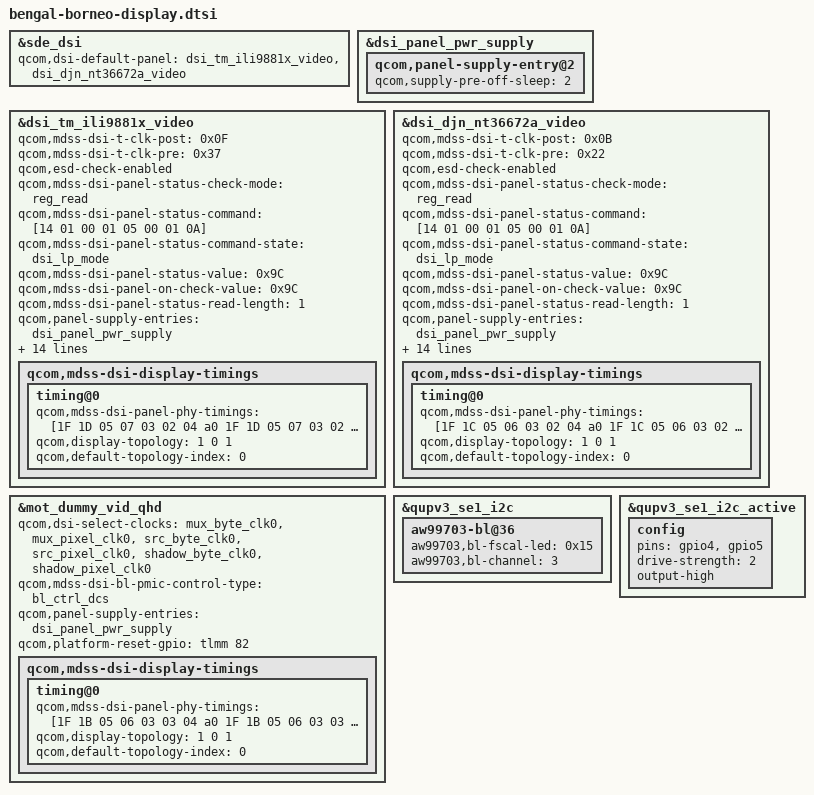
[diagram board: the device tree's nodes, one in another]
#include <dt-bindings/clock/mdss-14nm-pll-clk.h>
#include "bengal-sde-display.dtsi"
#include "bengal-leds-aw99703.dtsi"
#include "dsi-panel-mot-dummy-qhd-video.dtsi"
#include "dsi-panel-moto-ili9881x-tm-hdplus-video.dtsi"
#include "dsi-panel-moto-nt36672a-djn-hdplus-video.dtsi"

&sde_dsi {
    qcom,dsi-default-panel = <&dsi_tm_ili9881x_video &dsi_djn_nt36672a_video>;
};

&dsi_panel_pwr_supply {
	qcom,panel-supply-entry@2 {
		qcom,supply-pre-off-sleep = <2>;
	};
};

&dsi_tm_ili9881x_video {
	qcom,mdss-dsi-t-clk-post = <0x0F>;
	qcom,mdss-dsi-t-clk-pre = <0x37>;
	qcom,esd-check-enabled;
	qcom,mdss-dsi-panel-status-check-mode = "reg_read";
	qcom,mdss-dsi-panel-status-command = [14 01 00 01 05 00 01 0A];
	qcom,mdss-dsi-panel-status-command-state = "dsi_lp_mode";
	qcom,mdss-dsi-panel-status-value = <0x9C>;
	qcom,mdss-dsi-panel-on-check-value = <0x9C>;
	qcom,mdss-dsi-panel-status-read-length = <1>;
	qcom,panel-supply-entries = <&dsi_panel_pwr_supply>;
	qcom,mdss-dsi-bl-pmic-control-type = "bl_ctrl_i2c";
	qcom,mdss-dsi-bl-min-level = <1>;
	qcom,mdss-dsi-bl-max-level = <2047>;
	qcom,mdss-dsi-hbm-type = "lcd-dcs-wled";
	qcom,tp_state_check_enable;
	qcom,platform-reset-gpio-always-on;
	qcom,mdss-dsi-reset-force-pull-low;
	qcom,platform-reset-gpio = <&tlmm 82 0>;
	qcom,mdss-dsi-panel-supplier = "tianma";

	qcom,dsi-select-clocks = "mux_byte_clk0", "mux_pixel_clk0",
				"src_byte_clk0", "src_pixel_clk0",
				"shadow_byte_clk0", "shadow_pixel_clk0";

	qcom,mdss-dsi-display-timings {
		timing@0 {
			qcom,mdss-dsi-panel-phy-timings =
				[1F 1D 05 07 03 02 04 a0
				1F 1D 05 07 03 02 04 a0
				1F 1D 05 07 03 02 04 a0
				1F 1D 05 07 03 02 04 a0
				1F 11 05 06 03 02 04 a0];
			qcom,display-topology = <1 0 1>;
			qcom,default-topology-index = <0>;
		};
	};
};

&dsi_djn_nt36672a_video {
	qcom,mdss-dsi-t-clk-post = <0x0B>;
	qcom,mdss-dsi-t-clk-pre = <0x22>;
	qcom,esd-check-enabled;
	qcom,mdss-dsi-panel-status-check-mode = "reg_read";
	qcom,mdss-dsi-panel-status-command = [14 01 00 01 05 00 01 0A];
	qcom,mdss-dsi-panel-status-command-state = "dsi_lp_mode";
	qcom,mdss-dsi-panel-status-value = <0x9C>;
	qcom,mdss-dsi-panel-on-check-value = <0x9C>;
	qcom,mdss-dsi-panel-status-read-length = <1>;
	qcom,panel-supply-entries = <&dsi_panel_pwr_supply>;
	qcom,mdss-dsi-bl-pmic-control-type = "bl_ctrl_i2c";
	qcom,mdss-dsi-bl-min-level = <1>;
	qcom,mdss-dsi-bl-max-level = <2047>;
	qcom,mdss-dsi-hbm-type = "lcd-dcs-wled";
	qcom,tp_state_check_enable;
	qcom,platform-reset-gpio-always-on;
	qcom,mdss-dsi-reset-force-pull-low;
	qcom,platform-reset-gpio = <&tlmm 82 0>;
	qcom,mdss-dsi-panel-supplier = "djn";

	qcom,dsi-select-clocks = "mux_byte_clk0", "mux_pixel_clk0",
				"src_byte_clk0", "src_pixel_clk0",
				"shadow_byte_clk0", "shadow_pixel_clk0";

	qcom,mdss-dsi-display-timings {
		timing@0 {
			qcom,mdss-dsi-panel-phy-timings =
				[1F 1C 05 06 03 02 04 a0
				1F 1C 05 06 03 02 04 a0
				1F 1C 05 06 03 02 04 a0
				1F 1C 05 06 03 02 04 a0
				1F 10 05 06 03 02 04 a0];
			qcom,display-topology = <1 0 1>;
			qcom,default-topology-index = <0>;
		};
	};
};

&mot_dummy_vid_qhd {
	qcom,dsi-select-clocks = "mux_byte_clk0", "mux_pixel_clk0",
				"src_byte_clk0", "src_pixel_clk0",
				"shadow_byte_clk0", "shadow_pixel_clk0";

	qcom,mdss-dsi-bl-pmic-control-type = "bl_ctrl_dcs";
	qcom,panel-supply-entries = <&dsi_panel_pwr_supply>;
	qcom,platform-reset-gpio = <&tlmm 82 0>;

	qcom,mdss-dsi-display-timings {
		timing@0 {
			qcom,mdss-dsi-panel-phy-timings =
				[1F 1B 05 06 03 03 04 a0
				1F 1B 05 06 03 03 04 a0
				1F 1B 05 06 03 03 04 a0
				1F 1B 05 06 03 03 04 a0
				1F 10 04 06 03 03 04 a0];
			qcom,display-topology = <1 0 1>;
			qcom,default-topology-index = <0>;
		};
	};
};

&qupv3_se1_i2c {
    aw99703-bl@36 {
	aw99703,bl-fscal-led = <0x15>;/*default 21mA*/
        aw99703,bl-channel = <3>;
    };
};

&qupv3_se1_i2c_active {
	/delete-node/ config;
	config {
		pins = "gpio4", "gpio5";
		drive-strength = <2>;
		output-high;
	};
};
